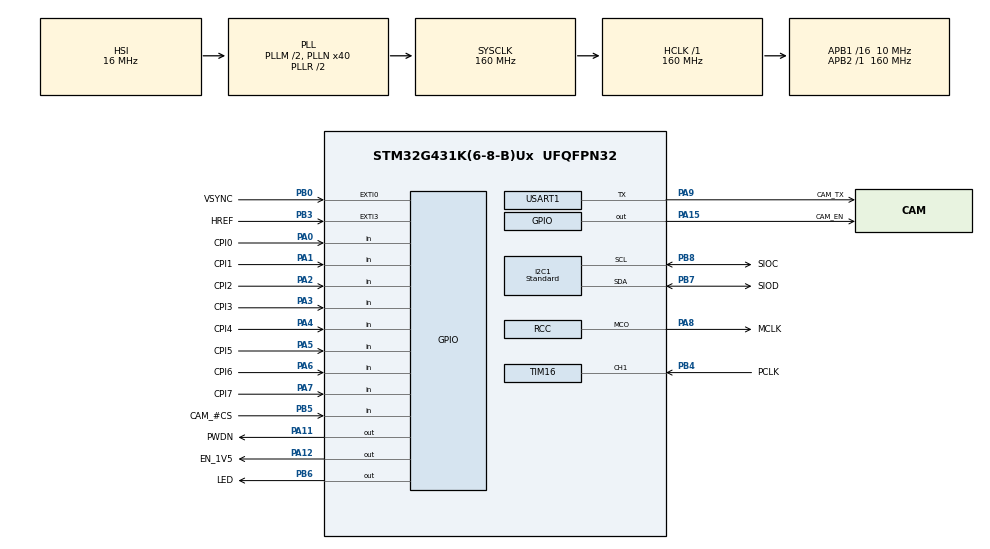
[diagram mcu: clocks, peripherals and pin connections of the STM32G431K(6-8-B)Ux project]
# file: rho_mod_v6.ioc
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Dma.Request0=TIM16_CH1
Dma.Request1=USART1_TX
Dma.TIM16_CH1.0.Direction=DMA_PERIPH_TO_MEMORY
Dma.TIM16_CH1.0.EventEnable=DISABLE
Dma.TIM16_CH1.0.Instance=DMA1_Channel1
Dma.TIM16_CH1.0.MemDataAlignment=DMA_MDATAALIGN_BYTE
Dma.TIM16_CH1.0.MemInc=DMA_MINC_ENABLE
Dma.TIM16_CH1.0.Mode=DMA_NORMAL
Dma.TIM16_CH1.0.PeriphDataAlignment=DMA_PDATAALIGN_BYTE
Dma.TIM16_CH1.0.PeriphInc=DMA_PINC_DISABLE
Dma.TIM16_CH1.0.Polarity=HAL_DMAMUX_REQ_GEN_RISING
Dma.TIM16_CH1.0.Priority=DMA_PRIORITY_VERY_HIGH
Dma.TIM16_CH1.0.RequestNumber=1
Dma.TIM16_CH1.0.SignalID=NONE
Dma.TIM16_CH1.0.SyncEnable=DISABLE
Dma.TIM16_CH1.0.SyncPolarity=HAL_DMAMUX_SYNC_NO_EVENT
Dma.TIM16_CH1.0.SyncRequestNumber=1
Dma.TIM16_CH1.0.SyncSignalID=NONE
Dma.USART1_TX.1.Direction=DMA_MEMORY_TO_PERIPH
Dma.USART1_TX.1.EventEnable=DISABLE
Dma.USART1_TX.1.Instance=DMA2_Channel2
Dma.USART1_TX.1.MemDataAlignment=DMA_MDATAALIGN_BYTE
Dma.USART1_TX.1.MemInc=DMA_MINC_ENABLE
Dma.USART1_TX.1.Mode=DMA_NORMAL
Dma.USART1_TX.1.PeriphDataAlignment=DMA_PDATAALIGN_BYTE
Dma.USART1_TX.1.PeriphInc=DMA_PINC_DISABLE
Dma.USART1_TX.1.Polarity=HAL_DMAMUX_REQ_GEN_RISING
Dma.USART1_TX.1.Priority=DMA_PRIORITY_VERY_HIGH
Dma.USART1_TX.1.RequestNumber=1
Dma.USART1_TX.1.SignalID=NONE
Dma.USART1_TX.1.SyncEnable=DISABLE
Dma.USART1_TX.1.SyncPolarity=HAL_DMAMUX_SYNC_NO_EVENT
Dma.USART1_TX.1.SyncRequestNumber=1
Dma.USART1_TX.1.SyncSignalID=NONE
I2C1.CustomTiming=Disabled
I2C1.I2C_Speed_Mode=I2C_Standard
I2C1.Timing=0x00202538
Mcu.Family=STM32G4
Mcu.Name=STM32G431K(6-8-B)Ux
Mcu.Package=UFQFPN32
NVIC.DMA1_Channel1_IRQn=true\:0\:0\:false\:false\:true\:true\:true
NVIC.DMA2_Channel2_IRQn=true\:0\:0\:false\:false\:true\:false\:true
NVIC.EXTI0_IRQn=true\:1\:1\:true\:false\:true\:true\:true
NVIC.EXTI3_IRQn=true\:1\:0\:true\:false\:true\:true\:true
NVIC.PriorityGroup=NVIC_PRIORITYGROUP_2
NVIC.USART1_IRQn=true\:0\:0\:false\:false\:true\:true\:true
PA0.GPIO_Label=CPI0
PA0.GPIO_Mode=GPIO_MODE_INPUT
PA0.GPIO_PuPd=GPIO_PULLUP
PA0.Signal=GPIO_Input
PA1.GPIO_Label=CPI1
PA1.GPIO_Mode=GPIO_MODE_INPUT
PA1.GPIO_PuPd=GPIO_PULLDOWN
PA1.Signal=GPIO_Input
PA10.GPIO_Label=CAM_RX
PA10.Signal=USART1_RX
PA11.GPIO_Label=PWDN
PA11.Signal=GPIO_Output
PA12.GPIO_Label=EN_1V5
PA12.Signal=GPIO_Output
PA13.Signal=SYS_JTMS-SWDIO
PA14.Signal=SYS_JTCK-SWCLK
PA15.GPIO_Label=CAM_EN
PA15.GPIO_PuPd=GPIO_PULLUP
PA15.Signal=GPIO_Output
PA2.GPIO_Label=CPI2
PA2.GPIO_Mode=GPIO_MODE_INPUT
PA2.GPIO_PuPd=GPIO_PULLUP
PA2.Signal=GPIO_Input
PA3.GPIO_Label=CPI3
PA3.GPIO_Mode=GPIO_MODE_INPUT
PA3.GPIO_PuPd=GPIO_PULLDOWN
PA3.Signal=GPIO_Input
PA4.GPIO_Label=CPI4
PA4.GPIO_Mode=GPIO_MODE_INPUT
PA4.GPIO_PuPd=GPIO_PULLUP
PA4.Signal=GPIO_Input
PA5.GPIO_Label=CPI5
PA5.GPIO_Mode=GPIO_MODE_INPUT
PA5.GPIO_PuPd=GPIO_PULLDOWN
PA5.Signal=GPIO_Input
PA6.GPIO_Label=CPI6
PA6.GPIO_Mode=GPIO_MODE_INPUT
PA6.GPIO_PuPd=GPIO_PULLUP
PA6.Signal=GPIO_Input
PA7.GPIO_Label=CPI7
PA7.GPIO_Mode=GPIO_MODE_INPUT
PA7.GPIO_PuPd=GPIO_PULLDOWN
PA7.Signal=GPIO_Input
PA8.GPIO_Label=MCLK
PA8.GPIO_Speed=GPIO_SPEED_FREQ_VERY_HIGH
PA8.Mode=Clock-out
PA8.Signal=RCC_MCO
PA9.GPIO_Label=CAM_TX
PA9.GPIO_Speed=GPIO_SPEED_FREQ_VERY_HIGH
PA9.Mode=Half_duplex(single_wire_mode)
PA9.Signal=USART1_TX
PB0.GPIO_Label=VSYNC
PB0.GPIO_ModeDefaultEXTI=GPIO_MODE_IT_RISING_FALLING
PB0.Signal=GPXTI0
PB3.GPIO_Label=HREF
PB3.GPIO_ModeDefaultEXTI=GPIO_MODE_IT_RISING_FALLING
PB3.Signal=GPXTI3
PB4.GPIO_Label=PCLK
PB4.GPIO_Speed=GPIO_SPEED_FREQ_VERY_HIGH
PB4.Signal=S_TIM16_CH1
PB5.GPIO_Label=CAM_\#CS
PB5.Signal=GPIO_Input
PB6.GPIO_FM6=SYSCFG_FASTMODEPLUS_PB6
PB6.GPIO_Label=LED
PB6.GPIO_PuPd=GPIO_PULLUP
PB6.GPIO_Speed=GPIO_SPEED_FREQ_VERY_HIGH
PB6.Signal=GPIO_Output
PB7.GPIO_Label=SIOD
PB7.GPIO_Pu=GPIO_PULLUP
PB7.GPIO_Speed=GPIO_SPEED_FREQ_HIGH
PB7.Mode=I2C
PB7.Signal=I2C1_SDA
PB8-BOOT0.GPIO_Label=SIOC
PB8-BOOT0.GPIO_Pu=GPIO_PULLUP
PB8-BOOT0.GPIO_Speed=GPIO_SPEED_FREQ_HIGH
PB8-BOOT0.Mode=I2C
PB8-BOOT0.Signal=I2C1_SCL
PF0-OSC_IN.Signal=RCC_OSC_IN
PF1-OSC_OUT.Signal=RCC_OSC_OUT
ProjectManager.HeapSize=0x200
ProjectManager.StackSize=0x400
ProjectManager.TargetToolchain=STM32CubeIDE
RCC.ADC12Freq_Value=160000000
RCC.AHBFreq_Value=160000000
RCC.APB1CLKDivider=RCC_HCLK_DIV16
RCC.APB1Freq_Value=10000000
RCC.APB1TimFreq_Value=20000000
RCC.APB2Freq_Value=160000000
RCC.APB2TimFreq_Value=160000000
RCC.CortexFreq_Value=160000000
RCC.EXTERNAL_CLOCK_VALUE=12288000
RCC.HCLKFreq_Value=160000000
RCC.HSE_VALUE=4000000
RCC.HSI48_VALUE=48000000
RCC.HSI_VALUE=16000000
RCC.LSE_VALUE=32768
RCC.PLLM=RCC_PLLM_DIV2
RCC.PLLN=40
RCC.RCC_MCO1Source=RCC_MCO1SOURCE_HSI48
RCC.RCC_MCODiv=RCC_MCODIV_8
RCC.SYSCLKFreq_VALUE=160000000
RCC.SYSCLKSource=RCC_SYSCLKSOURCE_PLLCLK
RCC.USBFreq_Value=160000000
RCC.VCOOutputFreq_Value=320000000
SH.S_TIM16_CH1.0=TIM16_CH1,Input_Capture1_from_TI1
TIM16.AutoReloadPreload=TIM_AUTORELOAD_PRELOAD_ENABLE
TIM16.Channel=TIM_CHANNEL_1
TIM16.ICPolarity_CH1=TIM_INPUTCHANNELPOLARITY_RISING
TIM16.PeriodNoDither=0
USART1.BaudRate=115200
USART1.FIFOMode=FIFOMODE_DISABLE
USART1.Mode=MODE_TX
USART1.OverSampling=UART_OVERSAMPLING_8
USART1.VirtualMode-Half_duplex(single_wire_mode)=VM_ASYNC
USART1.WordLength=WORDLENGTH_8B
VP_SYS_VS_DBSignals.Mode=DisableDeadBatterySignals
VP_TIM16_VS_ClockSourceINT.Mode=Enable_Timer
board=custom

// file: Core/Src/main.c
/* USER CODE BEGIN Header */
/**
  ******************************************************************************
  * @file           : main.c
  * @brief          : Main program body
  ******************************************************************************
  * @attention
  *
  * <h2><center>&copy; Copyright (c) 2021 STMicroelectronics.
  * All rights reserved.</center></h2>
  *
  * This software component is licensed by ST under BSD 3-Clause license,
  * the "License"; You may not use this file except in compliance with the
  * License. You may obtain a copy of the License at:
  *                        opensource.org/licenses/BSD-3-Clause
  *
  ******************************************************************************
  */
/* USER CODE END Header */
#include "main.h"

/* USER CODE BEGIN Includes */
#include "master.h"
/* USER CODE END Includes */

I2C_HandleTypeDef hi2c1;

TIM_HandleTypeDef htim16;
DMA_HandleTypeDef hdma_tim16_ch1;

UART_HandleTypeDef huart1;
DMA_HandleTypeDef hdma_usart1_tx;

void SystemClock_Config(void);
static void MX_GPIO_Init(void);
static void MX_I2C1_Init(void);
static void MX_DMA_Init(void);
static void MX_USART1_UART_Init(void);
static void MX_TIM16_Init(void);

/* USER CODE BEGIN 0 */
int _write(int file, char *ptr, int len)
{
	while(huart1.gState == HAL_UART_STATE_BUSY_TX);
	HAL_StatusTypeDef status = HAL_UART_Transmit_DMA(&huart1, (uint8_t*)ptr, len);
	return (int)status;
}
/* USER CODE END 0 */

int main(void)
{

  /* MCU Configuration--------------------------------------------------------*/

  /* Reset of all peripherals, Initializes the Flash interface and the Systick. */
  HAL_Init();

  /* Configure the system clock */
  SystemClock_Config();

  /* Initialize all configured peripherals */
  MX_GPIO_Init();
  MX_I2C1_Init();
  MX_DMA_Init();
  MX_USART1_UART_Init();
  MX_TIM16_Init();
  /* USER CODE BEGIN 2 */
  printf("Starting...\r\n");
  MasterFunctions.Connect( &hi2c1, &htim16, &huart1 );
  /* USER CODE END 2 */

  /* Infinite loop */
  /* USER CODE BEGIN WHILE */
  while (1)
  {
//	  printf("%d\r\n", (int)htim3.Instance->CNT);
//	  HAL_Delay(200);
    /* USER CODE END WHILE */

  }
}

void SystemClock_Config(void)
{
  RCC_OscInitTypeDef RCC_OscInitStruct = {0};
  RCC_ClkInitTypeDef RCC_ClkInitStruct = {0};
  RCC_PeriphCLKInitTypeDef PeriphClkInit = {0};

  /** Configure the main internal regulator output voltage
  */
  HAL_PWREx_ControlVoltageScaling(PWR_REGULATOR_VOLTAGE_SCALE1_BOOST);
  /** Initializes the RCC Oscillators according to the specified parameters
  * in the RCC_OscInitTypeDef structure.
  */
  RCC_OscInitStruct.OscillatorType = RCC_OSCILLATORTYPE_HSI|RCC_OSCILLATORTYPE_HSI48;
  RCC_OscInitStruct.HSIState = RCC_HSI_ON;
  RCC_OscInitStruct.HSICalibrationValue = RCC_HSICALIBRATION_DEFAULT;
  RCC_OscInitStruct.HSI48State = RCC_HSI48_ON;
  RCC_OscInitStruct.PLL.PLLState = RCC_PLL_ON;
  RCC_OscInitStruct.PLL.PLLSource = RCC_PLLSOURCE_HSI;
  RCC_OscInitStruct.PLL.PLLM = RCC_PLLM_DIV2;
  RCC_OscInitStruct.PLL.PLLN = 40;
  RCC_OscInitStruct.PLL.PLLP = RCC_PLLP_DIV2;
  RCC_OscInitStruct.PLL.PLLQ = RCC_PLLQ_DIV2;
  RCC_OscInitStruct.PLL.PLLR = RCC_PLLR_DIV2;
  if (HAL_RCC_OscConfig(&RCC_OscInitStruct) != HAL_OK)
  {
    Error_Handler();
  }
  /** Initializes the CPU, AHB and APB buses clocks
  */
  RCC_ClkInitStruct.ClockType = RCC_CLOCKTYPE_HCLK|RCC_CLOCKTYPE_SYSCLK
                              |RCC_CLOCKTYPE_PCLK1|RCC_CLOCKTYPE_PCLK2;
  RCC_ClkInitStruct.SYSCLKSource = RCC_SYSCLKSOURCE_PLLCLK;
  RCC_ClkInitStruct.AHBCLKDivider = RCC_SYSCLK_DIV1;
  RCC_ClkInitStruct.APB1CLKDivider = RCC_HCLK_DIV16;
  RCC_ClkInitStruct.APB2CLKDivider = RCC_HCLK_DIV1;

  if (HAL_RCC_ClockConfig(&RCC_ClkInitStruct, FLASH_LATENCY_4) != HAL_OK)
  {
    Error_Handler();
  }
  /** Initializes the peripherals clocks
  */
  PeriphClkInit.PeriphClockSelection = RCC_PERIPHCLK_USART1|RCC_PERIPHCLK_I2C1;
  PeriphClkInit.Usart1ClockSelection = RCC_USART1CLKSOURCE_PCLK2;
  PeriphClkInit.I2c1ClockSelection = RCC_I2C1CLKSOURCE_PCLK1;
  if (HAL_RCCEx_PeriphCLKConfig(&PeriphClkInit) != HAL_OK)
  {
    Error_Handler();
  }
  HAL_RCC_MCOConfig(RCC_MCO1, RCC_MCO1SOURCE_HSI48, RCC_MCODIV_8);
}

static void MX_I2C1_Init(void)
{

  hi2c1.Instance = I2C1;
  hi2c1.Init.Timing = 0x00202538;
  hi2c1.Init.OwnAddress1 = 0;
  hi2c1.Init.AddressingMode = I2C_ADDRESSINGMODE_7BIT;
  hi2c1.Init.DualAddressMode = I2C_DUALADDRESS_DISABLE;
  hi2c1.Init.OwnAddress2 = 0;
  hi2c1.Init.OwnAddress2Masks = I2C_OA2_NOMASK;
  hi2c1.Init.GeneralCallMode = I2C_GENERALCALL_DISABLE;
  hi2c1.Init.NoStretchMode = I2C_NOSTRETCH_DISABLE;
  if (HAL_I2C_Init(&hi2c1) != HAL_OK)
  {
    Error_Handler();
  }
  /** Configure Analogue filter
  */
  if (HAL_I2CEx_ConfigAnalogFilter(&hi2c1, I2C_ANALOGFILTER_ENABLE) != HAL_OK)
  {
    Error_Handler();
  }
  /** Configure Digital filter
  */
  if (HAL_I2CEx_ConfigDigitalFilter(&hi2c1, 0) != HAL_OK)
  {
    Error_Handler();
  }

}

static void MX_TIM16_Init(void)
{

  TIM_IC_InitTypeDef sConfigIC = {0};

  htim16.Instance = TIM16;
  htim16.Init.Prescaler = 0;
  htim16.Init.CounterMode = TIM_COUNTERMODE_UP;
  htim16.Init.Period = 0;
  htim16.Init.ClockDivision = TIM_CLOCKDIVISION_DIV1;
  htim16.Init.RepetitionCounter = 0;
  htim16.Init.AutoReloadPreload = TIM_AUTORELOAD_PRELOAD_ENABLE;
  if (HAL_TIM_Base_Init(&htim16) != HAL_OK)
  {
    Error_Handler();
  }
  if (HAL_TIM_IC_Init(&htim16) != HAL_OK)
  {
    Error_Handler();
  }
  sConfigIC.ICPolarity = TIM_INPUTCHANNELPOLARITY_RISING;
  sConfigIC.ICSelection = TIM_ICSELECTION_DIRECTTI;
  sConfigIC.ICPrescaler = TIM_ICPSC_DIV1;
  sConfigIC.ICFilter = 0;
  if (HAL_TIM_IC_ConfigChannel(&htim16, &sConfigIC, TIM_CHANNEL_1) != HAL_OK)
  {
    Error_Handler();
  }

}

static void MX_USART1_UART_Init(void)
{

  huart1.Instance = USART1;
  huart1.Init.BaudRate = 115200;
  huart1.Init.WordLength = UART_WORDLENGTH_8B;
  huart1.Init.StopBits = UART_STOPBITS_1;
  huart1.Init.Parity = UART_PARITY_NONE;
  huart1.Init.Mode = UART_MODE_TX;
  huart1.Init.HwFlowCtl = UART_HWCONTROL_NONE;
  huart1.Init.OverSampling = UART_OVERSAMPLING_8;
  huart1.Init.OneBitSampling = UART_ONE_BIT_SAMPLE_DISABLE;
  huart1.Init.ClockPrescaler = UART_PRESCALER_DIV1;
  huart1.AdvancedInit.AdvFeatureInit = UART_ADVFEATURE_NO_INIT;
  if (HAL_HalfDuplex_Init(&huart1) != HAL_OK)
  {
    Error_Handler();
  }
  if (HAL_UARTEx_SetTxFifoThreshold(&huart1, UART_TXFIFO_THRESHOLD_1_8) != HAL_OK)
  {
    Error_Handler();
  }
  if (HAL_UARTEx_SetRxFifoThreshold(&huart1, UART_RXFIFO_THRESHOLD_1_8) != HAL_OK)
  {
    Error_Handler();
  }
  if (HAL_UARTEx_DisableFifoMode(&huart1) != HAL_OK)
  {
    Error_Handler();
  }

}

static void MX_DMA_Init(void)
{

  /* DMA controller clock enable */
  __HAL_RCC_DMAMUX1_CLK_ENABLE();
  __HAL_RCC_DMA1_CLK_ENABLE();
  __HAL_RCC_DMA2_CLK_ENABLE();

  /* DMA interrupt init */
  /* DMA1_Channel1_IRQn interrupt configuration */
  HAL_NVIC_SetPriority(DMA1_Channel1_IRQn, 0, 0);
  HAL_NVIC_EnableIRQ(DMA1_Channel1_IRQn);
  /* DMA2_Channel2_IRQn interrupt configuration */
  HAL_NVIC_SetPriority(DMA2_Channel2_IRQn, 0, 0);
  HAL_NVIC_EnableIRQ(DMA2_Channel2_IRQn);

}

static void MX_GPIO_Init(void)
{
  GPIO_InitTypeDef GPIO_InitStruct = {0};

  /* GPIO Ports Clock Enable */
  __HAL_RCC_GPIOF_CLK_ENABLE();
  __HAL_RCC_GPIOG_CLK_ENABLE();
  __HAL_RCC_GPIOA_CLK_ENABLE();
  __HAL_RCC_GPIOB_CLK_ENABLE();

  /*Configure GPIO pin Output Level */
  HAL_GPIO_WritePin(GPIOA, PWDN_Pin|EN_1V5_Pin|CAM_EN_Pin, GPIO_PIN_RESET);

  /*Configure GPIO pin Output Level */
  HAL_GPIO_WritePin(LED_GPIO_Port, LED_Pin, GPIO_PIN_RESET);

  /*Configure GPIO pin : PG10 */
  GPIO_InitStruct.Pin = GPIO_PIN_10;
  GPIO_InitStruct.Mode = GPIO_MODE_ANALOG;
  GPIO_InitStruct.Pull = GPIO_NOPULL;
  HAL_GPIO_Init(GPIOG, &GPIO_InitStruct);

  /*Configure GPIO pins : CPI0_Pin CPI2_Pin CPI4_Pin CPI6_Pin */
  GPIO_InitStruct.Pin = CPI0_Pin|CPI2_Pin|CPI4_Pin|CPI6_Pin;
  GPIO_InitStruct.Mode = GPIO_MODE_INPUT;
  GPIO_InitStruct.Pull = GPIO_PULLUP;
  HAL_GPIO_Init(GPIOA, &GPIO_InitStruct);

  /*Configure GPIO pins : CPI1_Pin CPI3_Pin CPI5_Pin CPI7_Pin */
  GPIO_InitStruct.Pin = CPI1_Pin|CPI3_Pin|CPI5_Pin|CPI7_Pin;
  GPIO_InitStruct.Mode = GPIO_MODE_INPUT;
  GPIO_InitStruct.Pull = GPIO_PULLDOWN;
  HAL_GPIO_Init(GPIOA, &GPIO_InitStruct);

  /*Configure GPIO pins : VSYNC_Pin HREF_Pin */
  GPIO_InitStruct.Pin = VSYNC_Pin|HREF_Pin;
  GPIO_InitStruct.Mode = GPIO_MODE_IT_RISING_FALLING;
  GPIO_InitStruct.Pull = GPIO_NOPULL;
  HAL_GPIO_Init(GPIOB, &GPIO_InitStruct);

  /*Configure GPIO pin : MCLK_Pin */
  GPIO_InitStruct.Pin = MCLK_Pin;
  GPIO_InitStruct.Mode = GPIO_MODE_AF_PP;
  GPIO_InitStruct.Pull = GPIO_NOPULL;
  GPIO_InitStruct.Speed = GPIO_SPEED_FREQ_VERY_HIGH;
  GPIO_InitStruct.Alternate = GPIO_AF0_MCO;
  HAL_GPIO_Init(MCLK_GPIO_Port, &GPIO_InitStruct);

  /*Configure GPIO pins : PWDN_Pin EN_1V5_Pin */
  GPIO_InitStruct.Pin = PWDN_Pin|EN_1V5_Pin;
  GPIO_InitStruct.Mode = GPIO_MODE_OUTPUT_PP;
  GPIO_InitStruct.Pull = GPIO_NOPULL;
  GPIO_InitStruct.Speed = GPIO_SPEED_FREQ_LOW;
  HAL_GPIO_Init(GPIOA, &GPIO_InitStruct);

  /*Configure GPIO pin : CAM_EN_Pin */
  GPIO_InitStruct.Pin = CAM_EN_Pin;
  GPIO_InitStruct.Mode = GPIO_MODE_OUTPUT_PP;
  GPIO_InitStruct.Pull = GPIO_PULLUP;
  GPIO_InitStruct.Speed = GPIO_SPEED_FREQ_LOW;
  HAL_GPIO_Init(CAM_EN_GPIO_Port, &GPIO_InitStruct);

  /*Configure GPIO pin : CAM__CS_Pin */
  GPIO_InitStruct.Pin = CAM__CS_Pin;
  GPIO_InitStruct.Mode = GPIO_MODE_INPUT;
  GPIO_InitStruct.Pull = GPIO_NOPULL;
  HAL_GPIO_Init(CAM__CS_GPIO_Port, &GPIO_InitStruct);

  /*Configure GPIO pin : LED_Pin */
  GPIO_InitStruct.Pin = LED_Pin;
  GPIO_InitStruct.Mode = GPIO_MODE_OUTPUT_PP;
  GPIO_InitStruct.Pull = GPIO_PULLUP;
  GPIO_InitStruct.Speed = GPIO_SPEED_FREQ_VERY_HIGH;
  HAL_GPIO_Init(LED_GPIO_Port, &GPIO_InitStruct);

  /**/
  __HAL_SYSCFG_FASTMODEPLUS_ENABLE(SYSCFG_FASTMODEPLUS_PB6);

  /* EXTI interrupt init*/
  HAL_NVIC_SetPriority(EXTI0_IRQn, 1, 1);
  HAL_NVIC_EnableIRQ(EXTI0_IRQn);

  HAL_NVIC_SetPriority(EXTI3_IRQn, 1, 0);
  HAL_NVIC_EnableIRQ(EXTI3_IRQn);

}

void Error_Handler(void)
{
  __disable_irq();
  while (1)
  {
  }
}

/************************ (C) COPYRIGHT STMicroelectronics *****END OF FILE****/
